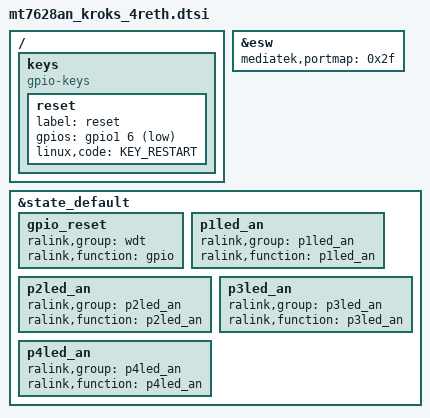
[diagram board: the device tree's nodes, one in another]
#include "mt7628an_kroks.dtsi"
#include "flash_kroks_16m.dtsi"

#include <dt-bindings/input/input.h>
#include <dt-bindings/gpio/gpio.h>

/ {
	keys {
		compatible = "gpio-keys";

		reset {
			label = "reset";
			gpios = <&gpio1 6 GPIO_ACTIVE_LOW>;
			linux,code = <KEY_RESTART>;
		};
	};
};

&esw {
	mediatek,portmap = <0x2f>;
};

&state_default {
	gpio_reset {
		ralink,group = "wdt";
		ralink,function = "gpio";
	};

	p1led_an {
		ralink,group = "p1led_an";
		ralink,function = "p1led_an";
	};

	p2led_an {
		ralink,group = "p2led_an";
		ralink,function = "p2led_an";
	};

	p3led_an {
		ralink,group = "p3led_an";
		ralink,function = "p3led_an";
	};

	p4led_an {
		ralink,group = "p4led_an";
		ralink,function = "p4led_an";
	};
};
